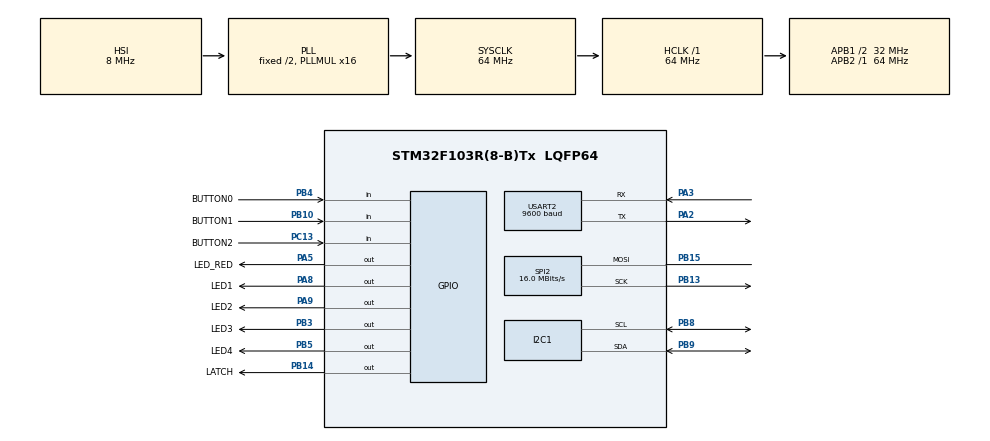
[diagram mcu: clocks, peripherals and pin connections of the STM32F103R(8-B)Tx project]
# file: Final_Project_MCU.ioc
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Mcu.Family=STM32F1
Mcu.Name=STM32F103R(8-B)Tx
Mcu.Package=LQFP64
NVIC.PriorityGroup=NVIC_PRIORITYGROUP_4
NVIC.TIM2_IRQn=true\:0\:0\:false\:false\:true\:true\:true\:true
NVIC.USART2_IRQn=true\:0\:0\:false\:false\:true\:true\:true\:true
PA13.Mode=Serial_Wire
PA13.Signal=SYS_JTMS-SWDIO
PA14.Mode=Serial_Wire
PA14.Signal=SYS_JTCK-SWCLK
PA2.Mode=Asynchronous
PA2.Signal=USART2_TX
PA3.Mode=Asynchronous
PA3.Signal=USART2_RX
PA5.GPIO_Label=LED_RED
PA5.Signal=GPIO_Output
PA8.GPIO_Label=LED1
PA8.Signal=GPIO_Output
PA9.GPIO_Label=LED2
PA9.Signal=GPIO_Output
PB10.GPIO_Label=BUTTON1
PB10.Signal=GPIO_Input
PB13.Mode=Simplex_Bidirectional_Master
PB13.Signal=SPI2_SCK
PB14.GPIO_Label=LATCH
PB14.Signal=GPIO_Output
PB15.Mode=Simplex_Bidirectional_Master
PB15.Signal=SPI2_MOSI
PB3.GPIO_Label=LED3
PB3.Signal=GPIO_Output
PB4.GPIO_Label=BUTTON0
PB4.Signal=GPIO_Input
PB5.GPIO_Label=LED4
PB5.Signal=GPIO_Output
PB8.Mode=I2C
PB8.Signal=I2C1_SCL
PB9.Mode=I2C
PB9.Signal=I2C1_SDA
PC13-TAMPER-RTC.GPIO_Label=BUTTON2
PC13-TAMPER-RTC.Signal=GPIO_Input
ProjectManager.HeapSize=0x200
ProjectManager.StackSize=0x400
ProjectManager.TargetToolchain=STM32CubeIDE
RCC.AHBFreq_Value=64000000
RCC.APB1CLKDivider=RCC_HCLK_DIV2
RCC.APB1Freq_Value=32000000
RCC.APB1TimFreq_Value=64000000
RCC.APB2Freq_Value=64000000
RCC.APB2TimFreq_Value=64000000
RCC.HCLKFreq_Value=64000000
RCC.PLLMUL=RCC_PLL_MUL16
RCC.SYSCLKFreq_VALUE=64000000
RCC.SYSCLKSource=RCC_SYSCLKSOURCE_PLLCLK
RCC.USBFreq_Value=64000000
SPI2.CalculateBaudRate=16.0 MBits/s
SPI2.Direction=SPI_DIRECTION_1LINE
SPI2.Mode=SPI_MODE_MASTER
SPI2.VirtualType=VM_MASTER
TIM2.Period=99
TIM2.Prescaler=6399
USART2.BaudRate=9600
USART2.VirtualMode=VM_ASYNC
VP_TIM2_VS_ClockSourceINT.Mode=Internal
board=custom

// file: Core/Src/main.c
/* USER CODE BEGIN Header */
/**
  ******************************************************************************
  * @file           : main.c
  * @brief          : Main program body
  ******************************************************************************
  * @attention
  *
  * <h2><center>&copy; Copyright (c) 2025 STMicroelectronics.
  * All rights reserved.</center></h2>
  *
  * This software component is licensed by ST under BSD 3-Clause license,
  * the "License"; You may not use this file except in compliance with the
  * License. You may obtain a copy of the License at:
  *                        opensource.org/licenses/BSD-3-Clause
  *
  ******************************************************************************
  */
/* USER CODE END Header */
#include "main.h"

I2C_HandleTypeDef hi2c1;

SPI_HandleTypeDef hspi2;

TIM_HandleTypeDef htim2;

UART_HandleTypeDef huart2;

void SystemClock_Config(void);
static void MX_GPIO_Init(void);
static void MX_TIM2_Init(void);
static void MX_I2C1_Init(void);
static void MX_USART2_UART_Init(void);
static void MX_SPI2_Init(void);
/* USER CODE BEGIN PFP */
void HAL_TIM_PeriodElapsedCallback(TIM_HandleTypeDef *htim);
/* USER CODE END PFP */

int main(void)
{

  /* MCU Configuration--------------------------------------------------------*/

  /* Reset of all peripherals, Initializes the Flash interface and the Systick. */
  HAL_Init();

  /* Configure the system clock */
  SystemClock_Config();

  /* Initialize all configured peripherals */
  MX_GPIO_Init();
  MX_TIM2_Init();
  MX_I2C1_Init();
  MX_USART2_UART_Init();
  MX_SPI2_Init();
  /* USER CODE BEGIN 2 */
  HAL_TIM_Base_Start_IT(&htim2);

  SCH_Init();
  lcd_init();

  SCH_Add_Task(blinkyLED, 0, 100);
  SCH_Add_Task(timerRun, 0, 10);
  SCH_Add_Task(getButtons, 0, 1);
  SCH_Add_Task(fsm, 0, 10);
  /* USER CODE END 2 */

  /* Infinite loop */
  /* USER CODE BEGIN WHILE */
  while (1)
  {
	  SCH_Dispatch_Tasks();
    /* USER CODE END WHILE */

  }
}

void SystemClock_Config(void)
{
  RCC_OscInitTypeDef RCC_OscInitStruct = {0};
  RCC_ClkInitTypeDef RCC_ClkInitStruct = {0};

  /** Initializes the RCC Oscillators according to the specified parameters
  * in the RCC_OscInitTypeDef structure.
  */
  RCC_OscInitStruct.OscillatorType = RCC_OSCILLATORTYPE_HSI;
  RCC_OscInitStruct.HSIState = RCC_HSI_ON;
  RCC_OscInitStruct.HSICalibrationValue = RCC_HSICALIBRATION_DEFAULT;
  RCC_OscInitStruct.PLL.PLLState = RCC_PLL_ON;
  RCC_OscInitStruct.PLL.PLLSource = RCC_PLLSOURCE_HSI_DIV2;
  RCC_OscInitStruct.PLL.PLLMUL = RCC_PLL_MUL16;
  if (HAL_RCC_OscConfig(&RCC_OscInitStruct) != HAL_OK)
  {
    Error_Handler();
  }
  /** Initializes the CPU, AHB and APB buses clocks
  */
  RCC_ClkInitStruct.ClockType = RCC_CLOCKTYPE_HCLK|RCC_CLOCKTYPE_SYSCLK
                              |RCC_CLOCKTYPE_PCLK1|RCC_CLOCKTYPE_PCLK2;
  RCC_ClkInitStruct.SYSCLKSource = RCC_SYSCLKSOURCE_PLLCLK;
  RCC_ClkInitStruct.AHBCLKDivider = RCC_SYSCLK_DIV1;
  RCC_ClkInitStruct.APB1CLKDivider = RCC_HCLK_DIV2;
  RCC_ClkInitStruct.APB2CLKDivider = RCC_HCLK_DIV1;

  if (HAL_RCC_ClockConfig(&RCC_ClkInitStruct, FLASH_LATENCY_2) != HAL_OK)
  {
    Error_Handler();
  }
}

static void MX_I2C1_Init(void)
{

  hi2c1.Instance = I2C1;
  hi2c1.Init.ClockSpeed = 100000;
  hi2c1.Init.DutyCycle = I2C_DUTYCYCLE_2;
  hi2c1.Init.OwnAddress1 = 0;
  hi2c1.Init.AddressingMode = I2C_ADDRESSINGMODE_7BIT;
  hi2c1.Init.DualAddressMode = I2C_DUALADDRESS_DISABLE;
  hi2c1.Init.OwnAddress2 = 0;
  hi2c1.Init.GeneralCallMode = I2C_GENERALCALL_DISABLE;
  hi2c1.Init.NoStretchMode = I2C_NOSTRETCH_DISABLE;
  if (HAL_I2C_Init(&hi2c1) != HAL_OK)
  {
    Error_Handler();
  }

}

static void MX_SPI2_Init(void)
{

  /* SPI2 parameter configuration*/
  hspi2.Instance = SPI2;
  hspi2.Init.Mode = SPI_MODE_MASTER;
  hspi2.Init.Direction = SPI_DIRECTION_1LINE;
  hspi2.Init.DataSize = SPI_DATASIZE_8BIT;
  hspi2.Init.CLKPolarity = SPI_POLARITY_LOW;
  hspi2.Init.CLKPhase = SPI_PHASE_1EDGE;
  hspi2.Init.NSS = SPI_NSS_SOFT;
  hspi2.Init.BaudRatePrescaler = SPI_BAUDRATEPRESCALER_2;
  hspi2.Init.FirstBit = SPI_FIRSTBIT_MSB;
  hspi2.Init.TIMode = SPI_TIMODE_DISABLE;
  hspi2.Init.CRCCalculation = SPI_CRCCALCULATION_DISABLE;
  hspi2.Init.CRCPolynomial = 10;
  if (HAL_SPI_Init(&hspi2) != HAL_OK)
  {
    Error_Handler();
  }

}

static void MX_TIM2_Init(void)
{

  TIM_ClockConfigTypeDef sClockSourceConfig = {0};
  TIM_MasterConfigTypeDef sMasterConfig = {0};

  htim2.Instance = TIM2;
  htim2.Init.Prescaler = 6399;
  htim2.Init.CounterMode = TIM_COUNTERMODE_UP;
  htim2.Init.Period = 99;
  htim2.Init.ClockDivision = TIM_CLOCKDIVISION_DIV1;
  htim2.Init.AutoReloadPreload = TIM_AUTORELOAD_PRELOAD_DISABLE;
  if (HAL_TIM_Base_Init(&htim2) != HAL_OK)
  {
    Error_Handler();
  }
  sClockSourceConfig.ClockSource = TIM_CLOCKSOURCE_INTERNAL;
  if (HAL_TIM_ConfigClockSource(&htim2, &sClockSourceConfig) != HAL_OK)
  {
    Error_Handler();
  }
  sMasterConfig.MasterOutputTrigger = TIM_TRGO_RESET;
  sMasterConfig.MasterSlaveMode = TIM_MASTERSLAVEMODE_DISABLE;
  if (HAL_TIMEx_MasterConfigSynchronization(&htim2, &sMasterConfig) != HAL_OK)
  {
    Error_Handler();
  }

}

static void MX_USART2_UART_Init(void)
{

  huart2.Instance = USART2;
  huart2.Init.BaudRate = 9600;
  huart2.Init.WordLength = UART_WORDLENGTH_8B;
  huart2.Init.StopBits = UART_STOPBITS_1;
  huart2.Init.Parity = UART_PARITY_NONE;
  huart2.Init.Mode = UART_MODE_TX_RX;
  huart2.Init.HwFlowCtl = UART_HWCONTROL_NONE;
  huart2.Init.OverSampling = UART_OVERSAMPLING_16;
  if (HAL_UART_Init(&huart2) != HAL_OK)
  {
    Error_Handler();
  }

}

static void MX_GPIO_Init(void)
{
  GPIO_InitTypeDef GPIO_InitStruct = {0};

  /* GPIO Ports Clock Enable */
  __HAL_RCC_GPIOC_CLK_ENABLE();
  __HAL_RCC_GPIOA_CLK_ENABLE();
  __HAL_RCC_GPIOB_CLK_ENABLE();

  /*Configure GPIO pin Output Level */
  HAL_GPIO_WritePin(GPIOA, LED_RED_Pin|LED1_Pin|LED2_Pin, GPIO_PIN_RESET);

  /*Configure GPIO pin Output Level */
  HAL_GPIO_WritePin(GPIOB, LATCH_Pin|LED3_Pin|LED4_Pin, GPIO_PIN_RESET);

  /*Configure GPIO pin : BUTTON2_Pin */
  GPIO_InitStruct.Pin = BUTTON2_Pin;
  GPIO_InitStruct.Mode = GPIO_MODE_INPUT;
  GPIO_InitStruct.Pull = GPIO_NOPULL;
  HAL_GPIO_Init(BUTTON2_GPIO_Port, &GPIO_InitStruct);

  /*Configure GPIO pins : LED_RED_Pin LED1_Pin LED2_Pin */
  GPIO_InitStruct.Pin = LED_RED_Pin|LED1_Pin|LED2_Pin;
  GPIO_InitStruct.Mode = GPIO_MODE_OUTPUT_PP;
  GPIO_InitStruct.Pull = GPIO_NOPULL;
  GPIO_InitStruct.Speed = GPIO_SPEED_FREQ_LOW;
  HAL_GPIO_Init(GPIOA, &GPIO_InitStruct);

  /*Configure GPIO pins : BUTTON1_Pin BUTTON0_Pin */
  GPIO_InitStruct.Pin = BUTTON1_Pin|BUTTON0_Pin;
  GPIO_InitStruct.Mode = GPIO_MODE_INPUT;
  GPIO_InitStruct.Pull = GPIO_NOPULL;
  HAL_GPIO_Init(GPIOB, &GPIO_InitStruct);

  /*Configure GPIO pins : LATCH_Pin LED3_Pin LED4_Pin */
  GPIO_InitStruct.Pin = LATCH_Pin|LED3_Pin|LED4_Pin;
  GPIO_InitStruct.Mode = GPIO_MODE_OUTPUT_PP;
  GPIO_InitStruct.Pull = GPIO_NOPULL;
  GPIO_InitStruct.Speed = GPIO_SPEED_FREQ_LOW;
  HAL_GPIO_Init(GPIOB, &GPIO_InitStruct);

}

/* USER CODE BEGIN 4 */
void HAL_TIM_PeriodElapsedCallback(TIM_HandleTypeDef *htim)
{
	SCH_Update();
}
/* USER CODE END 4 */

void Error_Handler(void)
{
  __disable_irq();
  while (1)
  {
  }
}

/************************ (C) COPYRIGHT STMicroelectronics *****END OF FILE****/
